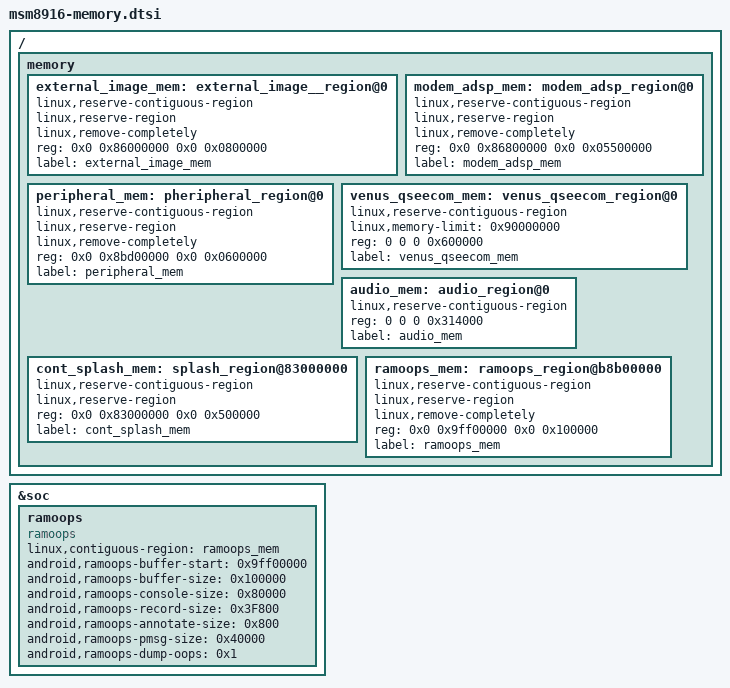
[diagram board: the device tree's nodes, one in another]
/* Copyright (c) 2014, The Linux Foundation. All rights reserved.
 *
 * This program is free software; you can redistribute it and/or modify
 * it under the terms of the GNU General Public License version 2 and
 * only version 2 as published by the Free Software Foundation.
 *
 * This program is distributed in the hope that it will be useful,
 * but WITHOUT ANY WARRANTY; without even the implied warranty of
 * MERCHANTABILITY or FITNESS FOR A PARTICULAR PURPOSE.  See the
 * GNU General Public License for more details.
 */

#include "msm8916-ion.dtsi"

/ {
	memory {
		#address-cells = <2>;
		#size-cells = <2>;

		external_image_mem: external_image__region@0 {
			linux,reserve-contiguous-region;
			linux,reserve-region;
			linux,remove-completely;
			reg = <0x0 0x86000000 0x0 0x0800000>;
			label = "external_image_mem";
		};

		modem_adsp_mem: modem_adsp_region@0 {
			linux,reserve-contiguous-region;
			linux,reserve-region;
			linux,remove-completely;
			reg = <0x0 0x86800000 0x0 0x05500000>;
			label = "modem_adsp_mem";
		};

		peripheral_mem: pheripheral_region@0 {
			linux,reserve-contiguous-region;
			linux,reserve-region;
			linux,remove-completely;
			reg = <0x0 0x8bd00000 0x0 0x0600000>;
			label = "peripheral_mem";
		};

		venus_qseecom_mem: venus_qseecom_region@0 {
			linux,reserve-contiguous-region;
			linux,memory-limit = <0x90000000>;
			reg = <0 0 0 0x600000>;
			label = "venus_qseecom_mem";
		};

		audio_mem: audio_region@0 {
			linux,reserve-contiguous-region;
			reg = <0 0 0 0x314000>;
			label = "audio_mem";
		};

		cont_splash_mem: splash_region@83000000 {
			linux,reserve-contiguous-region;
			linux,reserve-region;
			reg = <0x0 0x83000000 0x0 0x500000>;
			label = "cont_splash_mem";
		};

		ramoops_mem: ramoops_region@b8b00000 {
			linux,reserve-contiguous-region;
			linux,reserve-region;
			linux,remove-completely;
			reg = <0x0 0x9ff00000 0x0 0x100000>;
			label = "ramoops_mem";
		};
	};
};

&soc {
	ramoops {
		compatible = "ramoops";
		status = "ok";

		linux,contiguous-region = <&ramoops_mem>;

		android,ramoops-buffer-start = <0x9ff00000>;
		android,ramoops-buffer-size = <0x100000>;
		android,ramoops-console-size = <0x80000>;
		android,ramoops-record-size = <0x3F800>;
		android,ramoops-annotate-size = <0x800>;
		android,ramoops-pmsg-size = <0x40000>;
		android,ramoops-dump-oops = <0x1>;
	};
};
